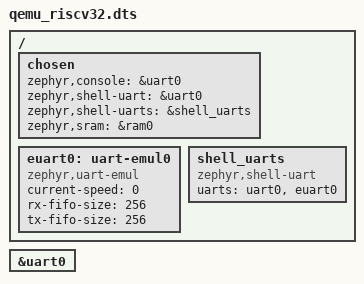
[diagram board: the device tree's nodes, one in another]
/* SPDX-License-Identifier: Apache-2.0 */

/dts-v1/;

#include <virt.dtsi>

/ {
	chosen {
		zephyr,console = &uart0;
		zephyr,shell-uart = &uart0;
		zephyr,shell-uarts = &shell_uarts;
		zephyr,sram = &ram0;
	};

	euart0: uart-emul0 {
		compatible = "zephyr,uart-emul";
		status = "okay";
		current-speed = <0>;
		rx-fifo-size = <256>;
		tx-fifo-size = <256>;
	};

	shell_uarts: shell_uarts {
		compatible = "zephyr,shell-uart";
		uarts = <&uart0 &euart0>;
		status = "okay";
	};
};

&uart0 {
	status = "okay";
};
